AUTOSAR XML (schema 4-2-2)
package /STELLANTIS/EPT/ASWCs
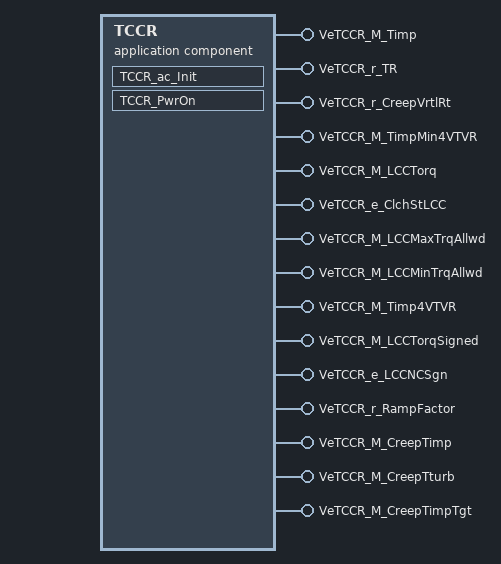
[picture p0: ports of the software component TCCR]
  application sw component type TCCR
    15 x provide port:
      VeTCCR_M_Timp: nonqueued-sender-com-spec{data-element=Value, init-value=0}, provided-interface=VeTCCR_M_Timp
      VeTCCR_r_TR: nonqueued-sender-com-spec{data-element=Value, init-value=0}, provided-interface=VeTCCR_r_TR
      VeTCCR_r_CreepVrtlRt: nonqueued-sender-com-spec{data-element=Value, init-value=0}, provided-interface=VeTCCR_r_CreepVrtlRt
      VeTCCR_M_TimpMin4VTVR: nonqueued-sender-com-spec{data-element=Value, init-value=0}, provided-interface=VeTCCR_M_TimpMin4VTVR
      VeTCCR_M_LCCTorq: nonqueued-sender-com-spec{data-element=Value, init-value=0}, provided-interface=VeTCCR_M_LCCTorq
      VeTCCR_e_ClchStLCC: nonqueued-sender-com-spec{data-element=Value, init-value=CeHCCR_e_ClInvalid}, provided-interface=VeTCCR_e_ClchStLCC
      VeTCCR_M_LCCMaxTrqAllwd: nonqueued-sender-com-spec{data-element=Value, init-value=0}, provided-interface=VeTCCR_M_LCCMaxTrqAllwd
      VeTCCR_M_LCCMinTrqAllwd: nonqueued-sender-com-spec{data-element=Value, init-value=0}, provided-interface=VeTCCR_M_LCCMinTrqAllwd
      VeTCCR_M_Timp4VTVR: nonqueued-sender-com-spec{data-element=Value, init-value=0}, provided-interface=VeTCCR_M_Timp4VTVR
      VeTCCR_M_LCCTorqSigned: nonqueued-sender-com-spec{data-element=Value, init-value=0}, provided-interface=VeTCCR_M_LCCTorqSigned
      VeTCCR_e_LCCNCSgn: nonqueued-sender-com-spec{data-element=Value, init-value=CeTMMR_e_UnknownNCSign}, provided-interface=VeTCCR_e_LCCNCSgn
      VeTCCR_r_RampFactor: nonqueued-sender-com-spec{data-element=Value, init-value=0}, provided-interface=VeTCCR_r_RampFactor
      VeTCCR_M_CreepTimp: nonqueued-sender-com-spec{data-element=Value, init-value=0}, provided-interface=VeTCCR_M_CreepTimp
      VeTCCR_M_CreepTturb: nonqueued-sender-com-spec{data-element=Value, init-value=0}, provided-interface=VeTCCR_M_CreepTturb
      VeTCCR_M_CreepTimpTgt: nonqueued-sender-com-spec{data-element=Value, init-value=0}, provided-interface=VeTCCR_M_CreepTimpTgt
    behavior IB_TCCR: data-type-mapping=msADTtoIDTMapping, handle-termination-and-restart=NO-SUPPORT, included-data-type-set=data-type=TeTCCR_e_LCCStatus
      init event Event_TCCR_ac_Init: start-on-event=TCCR_ac_Init
      init event Event_PwrOn: start-on-event=TCCR_PwrOn
      runnable TCCR_ac_Init
        data-send-points:
          access OUT_VeTCCR_e_ClchStLCC_Value: accessed-variable=VeTCCR_e_ClchStLCC.Value
          access OUT_VeTCCR_e_LCCNCSgn_Value: accessed-variable=VeTCCR_e_LCCNCSgn.Value
      runnable TCCR_PwrOn
        data-send-points:
          15 x access:
            OUT_VeTCCR_M_Timp_Value: accessed-variable=VeTCCR_M_Timp.Value
            OUT_VeTCCR_r_TR_Value: accessed-variable=VeTCCR_r_TR.Value
            OUT_VeTCCR_e_LCCNCSgn_Value: accessed-variable=VeTCCR_e_LCCNCSgn.Value
            OUT_VeTCCR_r_RampFactor_Value: accessed-variable=VeTCCR_r_RampFactor.Value
            OUT_VeTCCR_M_CreepTimp_Value: accessed-variable=VeTCCR_M_CreepTimp.Value
            OUT_VeTCCR_M_CreepTturb_Value: accessed-variable=VeTCCR_M_CreepTturb.Value
            OUT_VeTCCR_r_CreepVrtlRt_Value: accessed-variable=VeTCCR_r_CreepVrtlRt.Value
            OUT_VeTCCR_M_TimpMin4VTVR_Value: accessed-variable=VeTCCR_M_TimpMin4VTVR.Value
            OUT_VeTCCR_M_LCCTorq_Value: accessed-variable=VeTCCR_M_LCCTorq.Value
            OUT_VeTCCR_e_ClchStLCC_Value: accessed-variable=VeTCCR_e_ClchStLCC.Value
            OUT_VeTCCR_M_LCCMaxTrqAllwd_Value: accessed-variable=VeTCCR_M_LCCMaxTrqAllwd.Value
            OUT_VeTCCR_M_LCCMinTrqAllwd_Value: accessed-variable=VeTCCR_M_LCCMinTrqAllwd.Value
            OUT_VeTCCR_M_Timp4VTVR_Value: accessed-variable=VeTCCR_M_Timp4VTVR.Value
            OUT_VeTCCR_M_LCCTorqSigned_Value: accessed-variable=VeTCCR_M_LCCTorqSigned.Value
            OUT_VeTCCR_M_CreepTimpTgt_Value: accessed-variable=VeTCCR_M_CreepTimpTgt.Value
      variation point proxy Variant_TCCR_FUNC_EnblNiTgtLead: category=CONDITION, condition-access=0
      variation point proxy Variant_TCCR_FUNC_EnblTCC: category=CONDITION, condition-access=0
